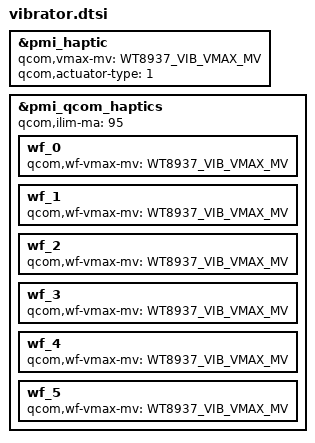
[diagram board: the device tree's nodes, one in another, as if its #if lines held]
#define WT8937_VIB_VMAX_MV 2700

#if !defined(CONFIG_INPUT_QTI_HAPTICS) || defined(CONFIG_PARSE_ANDROIDBOOT_MODE)
&pmi_haptic {
	qcom,vmax-mv = <WT8937_VIB_VMAX_MV>;
	qcom,actuator-type = <1>;
};
#endif

#ifdef CONFIG_INPUT_QTI_HAPTICS
&pmi_qcom_haptics {
	qcom,ilim-ma = <95>;
	wf_0 { qcom,wf-vmax-mv = <WT8937_VIB_VMAX_MV>; };
	wf_1 { qcom,wf-vmax-mv = <WT8937_VIB_VMAX_MV>; };
	wf_2 { qcom,wf-vmax-mv = <WT8937_VIB_VMAX_MV>; };
	wf_3 { qcom,wf-vmax-mv = <WT8937_VIB_VMAX_MV>; };
	wf_4 { qcom,wf-vmax-mv = <WT8937_VIB_VMAX_MV>; };
	wf_5 { qcom,wf-vmax-mv = <WT8937_VIB_VMAX_MV>; };
};
#endif
